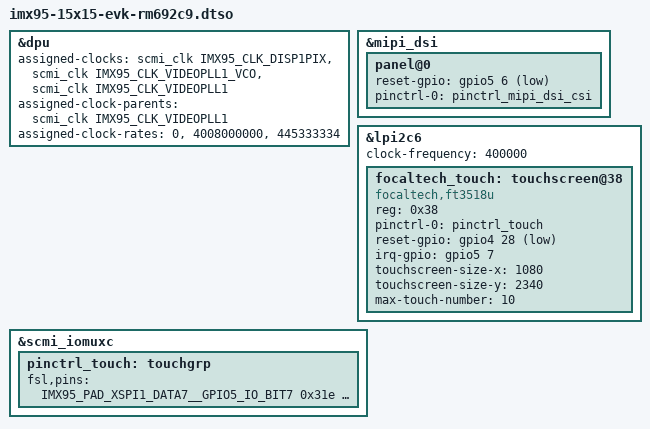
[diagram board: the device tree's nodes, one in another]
// SPDX-License-Identifier: (GPL-2.0+ OR MIT)
/*
 * Copyright 2024,2026 NXP
 */

#include <dt-bindings/gpio/gpio.h>

#include "imx95-clock.h"
#include "imx95-pinfunc.h"
#include "imx95-evk-rm692c9-common.dtsi"

&dpu {
	assigned-clocks = <&scmi_clk IMX95_CLK_DISP1PIX>,
			  <&scmi_clk IMX95_CLK_VIDEOPLL1_VCO>,
			  <&scmi_clk IMX95_CLK_VIDEOPLL1>;
	assigned-clock-parents = <&scmi_clk IMX95_CLK_VIDEOPLL1>;
	assigned-clock-rates = <0>, <4008000000>, <445333334>;
};

&mipi_dsi {
	panel@0 {
		reset-gpio = <&gpio5 6 GPIO_ACTIVE_LOW>;
		pinctrl-names = "default";
		pinctrl-0 = <&pinctrl_mipi_dsi_csi>;
	};
};

&lpi2c6 {
	#address-cells = <1>;
	#size-cells = <0>;
	clock-frequency = <400000>;

	focaltech_touch: touchscreen@38 {
		compatible = "focaltech,ft3518u";
		reg = <0x38>;
		pinctrl-names = "default";
		pinctrl-0 = <&pinctrl_touch>;
		reset-gpio = <&gpio4 28 GPIO_ACTIVE_LOW>;
		irq-gpio = <&gpio5 7 GPIO_ACTIVE_HIGH>;
		touchscreen-size-x = <1080>;
		touchscreen-size-y = <2340>;
		max-touch-number = <10>;
		status = "okay";
	};
};

&scmi_iomuxc {
	pinctrl_touch: touchgrp {
		fsl,pins = <
			IMX95_PAD_XSPI1_DATA7__GPIO5_IO_BIT7		0x31e
			IMX95_PAD_CCM_CLKO3__GPIO4_IO_BIT28		0x31e
		>;
	};
};
